AUTOSAR XML (schema 4-3-0)
package /ComponentTypes
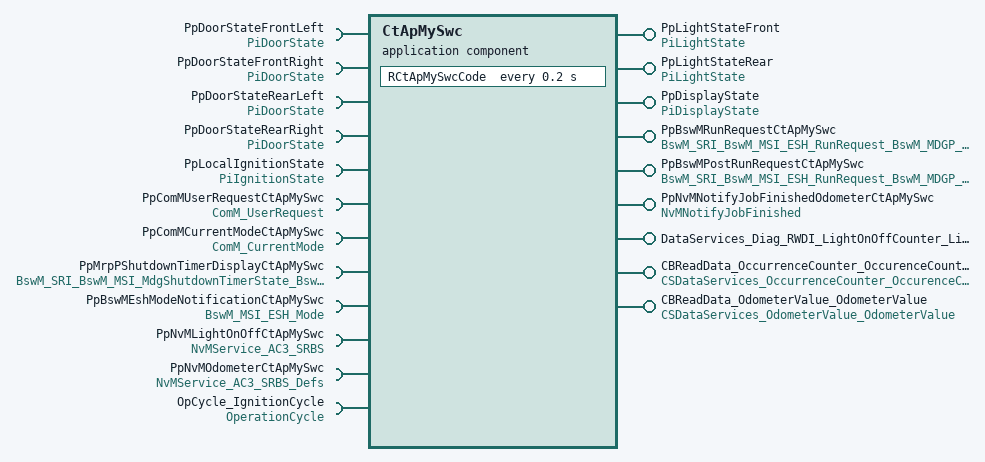
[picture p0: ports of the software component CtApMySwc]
  application sw component type CtApMySwc
    require port PpDoorStateFrontLeft: nonqueued-receiver-com-spec{data-element=DeDoorState, filter=data-filter-type=ALWAYS, init-value=constant-reference=CDoorClosed}, required-interface=PiDoorState
    require port PpDoorStateFrontRight: nonqueued-receiver-com-spec{data-element=DeDoorState, filter=data-filter-type=ALWAYS, init-value=constant-reference=CDoorClosed}, required-interface=PiDoorState
    provide port PpLightStateFront: nonqueued-sender-com-spec{data-element=DeLightState, init-value=constant-reference=CLightOff}, provided-interface=PiLightState
    require port PpDoorStateRearLeft: nonqueued-receiver-com-spec{data-element=DeDoorState, filter=data-filter-type=ALWAYS, init-value=0}, required-interface=PiDoorState
    require port PpDoorStateRearRight: nonqueued-receiver-com-spec{data-element=DeDoorState, filter=data-filter-type=ALWAYS, init-value=0}, required-interface=PiDoorState
    provide port PpLightStateRear: nonqueued-sender-com-spec{data-element=DeLightState, init-value=0}, provided-interface=PiLightState
    require port PpLocalIgnitionState: nonqueued-receiver-com-spec{data-element=DeIgnitionState, filter=data-filter-type=ALWAYS, init-value=1}, required-interface=PiIgnitionState
    provide port PpDisplayState: provided-interface=PiDisplayState
      provided-com-specs:
        data-element=DeDisplayBusState, init-value=constant-reference=CDisplayOff
        data-element=DeLightOnOffCounter, init-value=constant-reference=CUInt32Zero
        data-element=DeOdometerValue, init-value=constant-reference=CUInt32Zero
        data-element=DeOdometerWriteRequestPending, init-value=constant-reference=CWriteReqNotPending
    require port PpComMUserRequestCtApMySwc: required-com-specs=[RequestComMode, GetCurrentComMode, GetMaxComMode, GetRequestedComMode], required-interface=ComM_UserRequest
    provide port PpBswMRunRequestCtApMySwc: nonqueued-sender-com-spec=requestedMode, provided-interface=BswM_SRI_BswM_MSI_ESH_RunRequest_BswM_MDGP_ESH_RunRequest
    provide port PpBswMPostRunRequestCtApMySwc: nonqueued-sender-com-spec=requestedMode, provided-interface=BswM_SRI_BswM_MSI_ESH_RunRequest_BswM_MDGP_ESH_RunRequest
    5 x require port:
      PpComMCurrentModeCtApMySwc: mode-switch-receiver-com-spec=currentMode, required-interface=ComM_CurrentMode
      PpMrpPShutdownTimerDisplayCtApMySwc: nonqueued-receiver-com-spec=data-element=requestedMode, required-interface=BswM_SRI_BswM_MSI_MdgShutdownTimerState_BswM_MDGP_MdgShutdownTimerState
      PpBswMEshModeNotificationCtApMySwc: mode-switch-receiver-com-spec=BswM_MDGP_ESH_Mode, required-interface=BswM_MSI_ESH_Mode
      PpNvMLightOnOffCtApMySwc: required-com-specs=[WriteBlock, SetRamBlockStatus, ReadBlock, InvalidateNvBlock, GetErrorStatus, EraseBlock], required-interface=NvMService_AC3_SRBS
      PpNvMOdometerCtApMySwc: required-com-specs=[WriteBlock, SetRamBlockStatus, RestoreBlockDefaults, ReadBlock, InvalidateNvBlock, GetErrorStatus, EraseBlock], required-interface=NvMService_AC3_SRBS_Defs
    4 x provide port:
      PpNvMNotifyJobFinishedOdometerCtApMySwc: server-com-spec{operation=JobFinished, queue-length=1}, provided-interface=NvMNotifyJobFinished
      DataServices_Diag_RWDI_LightOnOffCounter_LightOnOffCounter_Value: provided-interface=DataServices_Diag_RWDI_LightOnOffCounter_LightOnOffCounter_Value
        provided-com-specs:
          operation=ReadData, queue-length=1
          operation=ConditionCheckRead, queue-length=1
          operation=WriteData, queue-length=1
      CBReadData_OccurrenceCounter_OccurenceCounter: server-com-spec{operation=ReadData, queue-length=1}, provided-interface=CSDataServices_OccurrenceCounter_OccurenceCounter
      CBReadData_OdometerValue_OdometerValue: server-com-spec{operation=ReadData, queue-length=1}, provided-interface=CSDataServices_OdometerValue_OdometerValue
    require port OpCycle_IgnitionCycle: required-com-specs=[GetOperationCycleState, SetOperationCycleState], required-interface=OperationCycle
    behavior CtApMySwc_InternalBehavior: data-type-mapping=DemoTypeMapping
      exclusive area ExArLightOnOffCounter
      exclusive area ExArOdometer
      ar-typed-per-instance-memorys:
        data PimOdometer: sw-calibration-access=READ-ONLY, type=AdtOdometer
        data PimLightOnOffCounter: sw-calibration-access=READ-ONLY, type=AdtLightOnOffCounter
      timing event TMT_RCtApMySwcCode: start-on-event=RCtApMySwcCode, period=0.2
      init event CtApMySwc_InitEvent: start-on-event=RCtApMySwcInit
      swc mode switch event MST_RCtApMySwcComM_ModeChange_FULL_COMM_Entry_0: start-on-event=RCtApMySwcComM_ModeChange_FULL_COMM_Entry, activation=ON-ENTRY, mode=PpComMCurrentModeCtApMySwc.currentMode.COMM_FULL_COMMUNICATION
      swc mode switch event MST_RCtApMySwcComM_ModeChange_FULL_COMM_Exit_0: start-on-event=RCtApMySwcComM_ModeChange_FULL_COMM_Exit, activation=ON-EXIT, mode=PpComMCurrentModeCtApMySwc.currentMode.COMM_FULL_COMMUNICATION
      data received event DRT_Runnable_PpMrpPShutdownTimerDisplayCtApMySwc_requestedMode: start-on-event=RCtApMySwcPostRunCode, data=PpMrpPShutdownTimerDisplayCtApMySwc.requestedMode
      swc mode switch event MST_RCtApMySwcPostRunCode_0: start-on-event=RCtApMySwcPostRunCode, activation=ON-ENTRY, mode=PpBswMEshModeNotificationCtApMySwc.BswM_MDGP_ESH_Mode.POSTRUN
      6 x operation invoked event:
        OIT_PpNvMNotifyJobFinishedOdometerCtApMySwc_JobFinished_PpNvMNotifyJobFinishedOdometerCtApMySwc_JobFinished: start-on-event=PpNvMNotifyJobFinishedOdometerCtApMySwc_JobFinished, operation=PpNvMNotifyJobFinishedOdometerCtApMySwc.JobFinished
        OIT_DataServices_Diag_RWDI_LightOnOffCounter_LightOnOffCounter_Value_WriteData_DataServices_Diag_RWDI_LightOnOffCounter_9798F8A6: start-on-event=DataServices_Diag_RWDI_LightOnOffCounter_LightOnOffCounter_Value_WriteData, operation=DataServices_Diag_RWDI_LightOnOffCounter_LightOnOffCounter_Value.WriteData
        OIT_DataServices_Diag_RWDI_LightOnOffCounter_LightOnOffCounter_Value_ConditionCheckRead_DataServices_Diag_RWDI_LightOnOf2065F94A: start-on-event=DataServices_Diag_RWDI_LightOnOffCounter_LightOnOffCounter_Value_ConditionCheckRead, operation=DataServices_Diag_RWDI_LightOnOffCounter_LightOnOffCounter_Value.ConditionCheckRead
        OIT_DataServices_Diag_RWDI_LightOnOffCounter_LightOnOffCounter_Value_ReadData_DataServices_Diag_RWDI_LightOnOffCounter_LBCB6C10A: start-on-event=DataServices_Diag_RWDI_LightOnOffCounter_LightOnOffCounter_Value_ReadData, operation=DataServices_Diag_RWDI_LightOnOffCounter_LightOnOffCounter_Value.ReadData
        OIT_CBReadData_OccurrenceCounter_OccurenceCounter_ReadData_CBReadData_OccurrenceCounter_OccurenceCounter_ReadData: start-on-event=CBReadData_OccurrenceCounter_OccurenceCounter_ReadData, operation=CBReadData_OccurrenceCounter_OccurenceCounter.ReadData
        OIT_CBReadData_OdometerValue_OdometerValue_ReadData_CBReadData_OdometerValue_OdometerValue_ReadData: start-on-event=CBReadData_OdometerValue_OdometerValue_ReadData, operation=CBReadData_OdometerValue_OdometerValue.ReadData
      explicit-inter-runnable-variables:
        data IrvDoorStateOld: type=uint16, init-value=constant-reference=CDoorClosed
      11 x runnable:
        RCtApMySwcCode: can-enter-exclusive-area=[ExArLightOnOffCounter, ExArOdometer]
          data-read-access:
            access READ_PpDoorStateFrontLeft_DeDoorState: accessed-variable=PpDoorStateFrontLeft.DeDoorState
            access REC_PpDoorStateRearLeft_DeDoorState: accessed-variable=PpDoorStateRearLeft.DeDoorState
          data-receive-point-by-arguments:
            access REC_PpDoorStateFrontRight_DeDoorState: accessed-variable=PpDoorStateFrontRight.DeDoorState
            access REC_PpDoorStateRearRight_DeDoorState: accessed-variable=PpDoorStateRearRight.DeDoorState
            access REC_PpLocalIgnitionState_DeIgnitionState: accessed-variable=PpLocalIgnitionState.DeIgnitionState
          data-send-points:
            7 x access:
              SEND_PpLightStateFront_DeLightState: accessed-variable=PpLightStateFront.DeLightState
              SEND_PpLightStateRear_DeLightState: accessed-variable=PpLightStateRear.DeLightState
              SEND_PpDisplayState_DeDisplayBusState: accessed-variable=PpDisplayState.DeDisplayBusState
              SEND_PpBswMRunRequestCtApMySwc_requestedMode: accessed-variable=PpBswMRunRequestCtApMySwc.requestedMode
              SEND_PpDisplayState_DeLightOnOffCounter: accessed-variable=PpDisplayState.DeLightOnOffCounter
              SEND_PpDisplayState_DeOdometerValue: accessed-variable=PpDisplayState.DeOdometerValue
              SEND_PpDisplayState_DeOdometerWriteRequestPending: accessed-variable=PpDisplayState.DeOdometerWriteRequestPending
          read-local-variables:
            access Read_IrvDoorStateOld: accessed-variable=IrvDoorStateOld
          4 x sync call:
            SC_PpComMUserRequestCtApMySwc_RequestComMode: operation=PpComMUserRequestCtApMySwc.RequestComMode
            SC_PpNvMLightOnOffCounterCtApMySwc_WriteBlock: operation=PpNvMLightOnOffCtApMySwc.WriteBlock
            SC_PpNvMPimOdometerCtApMySwc_GetErrorStatus: operation=PpNvMOdometerCtApMySwc.GetErrorStatus
            SC_PpNvMPimOdometerCtApMySwc_WriteBlock: operation=PpNvMOdometerCtApMySwc.WriteBlock
          written-local-variables:
            access WRITE_IrvDoorStateOld: accessed-variable=IrvDoorStateOld
        RCtApMySwcInit: can-enter-exclusive-area=ExArLightOnOffCounter
          data-send-points:
            access SEND_PpBswMPostRunRequestCtApMySwc_requestedMode: accessed-variable=PpBswMPostRunRequestCtApMySwc.requestedMode
            access SEND_PpBswMRunRequestCtApMySwc_requestedMode: accessed-variable=PpBswMRunRequestCtApMySwc.requestedMode
            access SEND_PpDisplayState_DeLightOnOffCounter: accessed-variable=PpDisplayState.DeLightOnOffCounter
          sync call SC_OpCycle_IgnitionCycle_SetOperationCycleState: operation=OpCycle_IgnitionCycle.SetOperationCycleState
        RCtApMySwcComM_ModeChange_FULL_COMM_Entry
          data-send-points:
            access SEND_PpDisplayState_DeDisplayBusState: accessed-variable=PpDisplayState.DeDisplayBusState
        RCtApMySwcComM_ModeChange_FULL_COMM_Exit
          data-send-points:
            access SEND_PpDisplayState_DeDisplayBusState: accessed-variable=PpDisplayState.DeDisplayBusState
        RCtApMySwcPostRunCode
          data-receive-point-by-arguments:
            access REC_PpMrpPShutdownTimerDisplayCtApMySwc_requestedMode: accessed-variable=PpMrpPShutdownTimerDisplayCtApMySwc.requestedMode
          data-send-points:
            access SEND_PpBswMPostRunRequestCtApMySwc_requestedMode: accessed-variable=PpBswMPostRunRequestCtApMySwc.requestedMode
            access SEND_PpLightStateFront_DeLightState: accessed-variable=PpLightStateFront.DeLightState
            access SEND_PpLightStateRear_DeLightState: accessed-variable=PpLightStateRear.DeLightState
          sync call SC_PpComMUserRequestCtApMySwc_RequestComMode: operation=PpComMUserRequestCtApMySwc.RequestComMode
        PpNvMNotifyJobFinishedOdometerCtApMySwc_JobFinished
          data-send-points:
            access SEND_PpDisplayState_DeOdometerWriteRequestPending: accessed-variable=PpDisplayState.DeOdometerWriteRequestPending
        DataServices_Diag_RWDI_LightOnOffCounter_LightOnOffCounter_Value_WriteData: can-enter-exclusive-area=ExArLightOnOffCounter
        DataServices_Diag_RWDI_LightOnOffCounter_LightOnOffCounter_Value_ConditionCheckRead: can-enter-exclusive-area=ExArLightOnOffCounter
        DataServices_Diag_RWDI_LightOnOffCounter_LightOnOffCounter_Value_ReadData: can-enter-exclusive-area=ExArLightOnOffCounter
        CBReadData_OccurrenceCounter_OccurenceCounter_ReadData
        CBReadData_OdometerValue_OdometerValue_ReadData: can-enter-exclusive-area=ExArOdometer
      swc service dependency SnNvMPimLightOnOffCounter: assigned-datas=role-based-data-assignment={role=ramBlock, used-data-element=PimLightOnOffCounter}, assigned-ports=role-based-port-assignment={port-prototype=PpNvMLightOnOffCtApMySwc, role=NvMService_AC3_SRBS}
        service-needs:
          nv block needs SnNvMPimLightOnOffCounter: readonly=false, resistant-to-changed-sw=false, restore-at-start=true, store-at-shutdown=true, write-only-once=false
      swc service dependency SnNvMPimOdometer
        assigned-datas:
          role=ramBlock, used-data-element=PimOdometer
          role=defaultValue, used-parameter-element=CalOdometer
        assigned-ports:
          port-prototype=PpNvMOdometerCtApMySwc, role=NvMService_AC3_SRBS_Defs
          port-prototype=PpNvMNotifyJobFinishedOdometerCtApMySwc, role=NvMNotifyJobFinished
        service-needs:
          nv block needs SnNvMPimOdometer: readonly=false, resistant-to-changed-sw=false, restore-at-start=true, store-at-shutdown=true, write-only-once=false
      shared-parameters:
        parameter data prototype CalOdometer: sw-calibration-access=READ-WRITE, type=AdtOdometer, init-value=constant-reference=COdometerDefault
  swc implementation CtApMySwc_Implementation: behavior=CtApMySwc_InternalBehavior
